AUTOSAR XML (schema 4-0-3)
standard types defined: UInt32, UInt8
package /AUTOSAR_Platform/DataConstrs
  range DC_UInt8: raw 0..255
package /PATAC/MSM/ComponentTypes
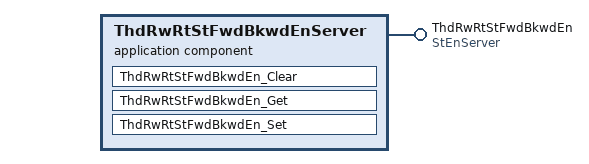
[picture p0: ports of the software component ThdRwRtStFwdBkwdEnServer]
  application sw component type ThdRwRtStFwdBkwdEnServer
    provide port ThdRwRtStFwdBkwdEn: provided-com-specs=[{operation=Clear, queue-length=1}, {operation=Get, queue-length=1}, {operation=Set, queue-length=1}], provided-interface=StEnServer
    behavior ThdRwRtStFwdBkwdEnServer_InternalBehavior
      operation invoked event OIT_ThdRwRtStFwdBkwdEn_Clear_ThdRwRtStFwdBkwdEn_Clear: start-on-event=ThdRwRtStFwdBkwdEn_Clear, operation=ThdRwRtStFwdBkwdEn.Clear
      operation invoked event OIT_ThdRwRtStFwdBkwdEn_Get_ThdRwRtStFwdBkwdEn_Get: start-on-event=ThdRwRtStFwdBkwdEn_Get, operation=ThdRwRtStFwdBkwdEn.Get
      operation invoked event OIT_ThdRwRtStFwdBkwdEn_Set_ThdRwRtStFwdBkwdEn_Set: start-on-event=ThdRwRtStFwdBkwdEn_Set, operation=ThdRwRtStFwdBkwdEn.Set
      runnable ThdRwRtStFwdBkwdEn_Clear
      runnable ThdRwRtStFwdBkwdEn_Get
      runnable ThdRwRtStFwdBkwdEn_Set
  swc implementation ThdRwRtStFwdBkwdEnServer_Implementation: behavior=ThdRwRtStFwdBkwdEnServer_InternalBehavior
    code-descriptors:
      code Default: artifact-descriptors=autosar-engineering-object={short-label=Default, category=SWSRC}
package /PATAC/MSM/ModeAdjust/PortInterface
  client server interface StEnServer
    operation Clear
      arg data: type=UInt8, direction=IN, server-argument-impl-policy=USE-ARGUMENT-TYPE
    operation Get
      arg data: type=UInt32, direction=OUT, server-argument-impl-policy=USE-ARGUMENT-TYPE
    operation Set
      arg data: type=UInt8, direction=IN, server-argument-impl-policy=USE-ARGUMENT-TYPE
